# APM32F051 register map
File version: 1.0
Registers are 32-bit, read-write, reset 0x0 unless marked. A register's access mark holds for its fields unless they carry their own. Offsets are from the block's base; [hi:lo] are bit positions; {n}, {i} and the like mark numbered series.

## ADC — Analog-to-digital converter
Base 0x40012400
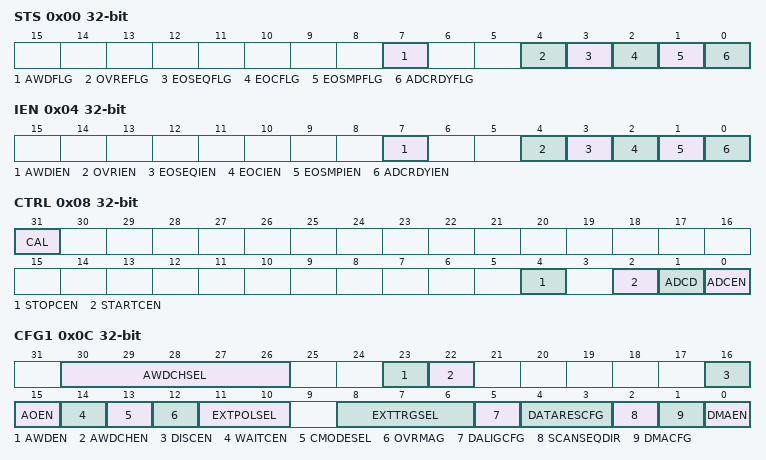
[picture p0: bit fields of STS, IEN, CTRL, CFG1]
0x00 STS — interrupt and status register
  [7] AWDFLG — Analog watchdog flag
  [4] OVREFLG — ADC overrun flag
  [3] EOSEQFLG — End of sequence flag
  [2] EOCFLG — End of conversion flag
  [1] EOSMPFLG — End of sampling flag
  [0] ADCRDYFLG — ADC ready flag
0x04 IEN — interrupt enable register
  [7] AWDIEN — Analog watchdog interrupt enable
  [4] OVRIEN — Overrun interrupt enable
  [3] EOSEQIEN — End of conversion sequence interrupt enable
  [2] EOCIEN — End of conversion interrupt enable
  [1] EOSMPIEN — End of sampling flag interrupt enable
  [0] ADCRDYIEN — ADC ready interrupt enable
0x08 CTRL — control register
  [31] CAL — ADC calibration
  [4] STOPCEN — ADC stop conversion command
  [2] STARTCEN — ADC start conversion command
  [1] ADCD — ADC disable command
  [0] ADCEN — ADC enable command
0x0C CFG1 — configuration register 1
  [30:26] AWDCHSEL — Analog watchdog channel selection
  [23] AWDEN — Analog watchdog enable
  [22] AWDCHEN — Enable the watchdog on a single channel or on all channels
  [16] DISCEN — Discontinuous mode
  [15] AOEN — Auto-off mode
  [14] WAITCEN — Auto-delayed conversion mode
  [13] CMODESEL — Single / continuous conversion mode
  [12] OVRMAG — Overrun management mode
  [11:10] EXTPOLSEL — External trigger enable and polarity selection
  [8:6] EXTTRGSEL — External trigger selection
  [5] DALIGCFG — Data alignment
  [4:3] DATARESCFG — Data resolution
  [2] SCANSEQDIR — Scan sequence direction
  [1] DMACFG — Direct memery access configuration
  [0] DMAEN — Direct memory access enable
0x10 CFG2 — configuration register 2
  [31:30] CLKCFG — ADC clock mode
0x14 SMPTIM — sampling time register
  [2:0] SMPCYCSEL — Sampling time selection
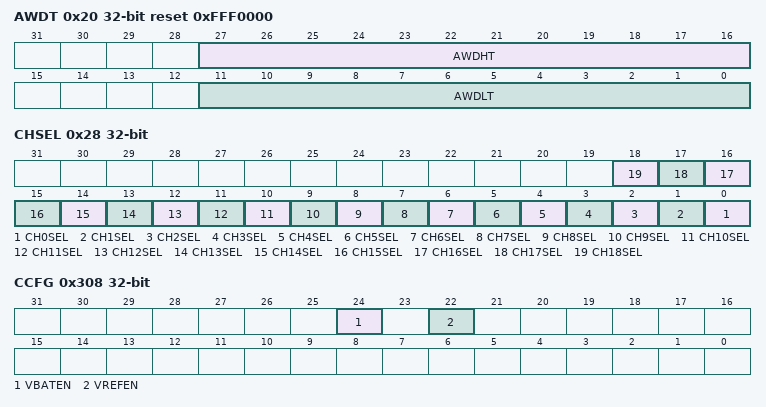
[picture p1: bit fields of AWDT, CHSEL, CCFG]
0x20 AWDT reset 0xFFF0000 — watchdog threshold register
  [27:16] AWDHT — Analog watchdog higher threshold
  [11:0] AWDLT — Analog watchdog lower threshold
0x28 CHSEL — channel selection register
  [n] CH{n}SEL (n=0..18) — Channel-{n} selection
0x40 DATA ro
  [15:0] CDATA — Converted data
0x308 CCFG — common configuration register
  [24] VBATEN — VBAT Enable
  [22] VREFEN — Temperature sensor and VREFINT enable

## DAC — Digital-to-Analog converter
Base 0x40007400
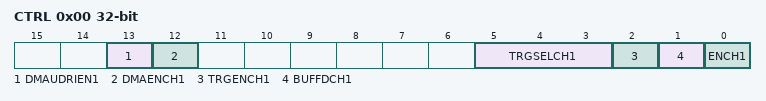
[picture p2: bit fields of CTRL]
0x00 CTRL — DAC control register
  [13] DMAUDRIEN1 — DAC channel1 DMA Underrun Interrupt enable
  [12] DMAENCH1 — DAC channel1 DMA enable
  [5:3] TRGSELCH1 — DAC channel1 trigger selection
  [2] TRGENCH1 — DAC channel1 trigger enable
  [1] BUFFDCH1 — DAC channel1 output buffer disable
  [0] ENCH1 — DAC channel1 enable
0x04 SWTRG wo — DAC software trigger register
  [0] SWTRG1 — DAC channel1 software trigger
0x08 DH12R1 — DAC channel1 12-bit right-aligned data holding register
  [11:0] DATA — DAC channel1 12-bit right-aligned data
0x0C DH12L1 — DAC channel1 12-bit left-aligned data holding register
  [15:4] DATA — DAC channel1 12-bit left-aligned data
0x10 DH8R1 — DAC channel1 8-bit right-aligned data holding register
  [7:0] DATA — DAC channel1 8-bit right-aligned data
0x28 DH8RDUAL — Dual DAC 8-bit right-aligned data holding register
  [7:0] DATACH1 — DAC channel1 8-bit right-aligned data
0x2C DATAOCH1 ro — DAC channel1 data output register
  [11:0] DATA — DAC channel1 data output
0x34 STS — DAC status register
  [13] DMAUDRFLG1 — DAC channel1 8-bit right-aligned data

## COMP — Comparator
Base 0x4001001C
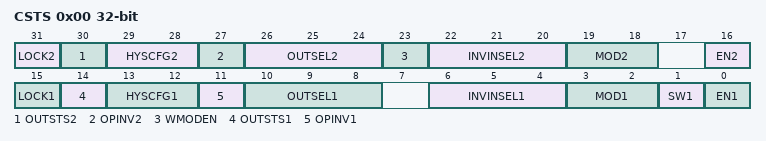
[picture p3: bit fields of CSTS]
0x00 CSTS access per field — control and status register
  [31] LOCK2 rw — Comparator 2 lock
  [30] OUTSTS2 ro — Comparator 2 output
  [29:28] HYSCFG2 rw — Comparator 2 hysteresis
  [27] OPINV2 rw — Comparator 2 output polarity
  [26:24] OUTSEL2 rw — Comparator 2 output selection
  [23] WMODEN rw — Window mode enable
  [22:20] INVINSEL2 rw — Comparator 2 inverting input selection
  [19:18] MOD2 rw — Comparator 2 mode
  [16] EN2 rw — Comparator 2 enable
  [15] LOCK1 rw — Comparator 1 lock
  [14] OUTSTS1 ro — Comparator 1 output
  [13:12] HYSCFG1 rw — Comparator 1 hysteresis
  [11] OPINV1 rw — Comparator 1 output polarity
  [10:8] OUTSEL1 rw — Comparator 1 output selection
  [6:4] INVINSEL1 rw — Comparator 1 inverting input selection
  [3:2] MOD1 rw — Comparator 1 mode
  [1] SW1 rw — COMP1SW
  [0] EN1 rw — Comparator 1 enable
